VERSION ""

NS_ :

BS_:

BU_: ECU

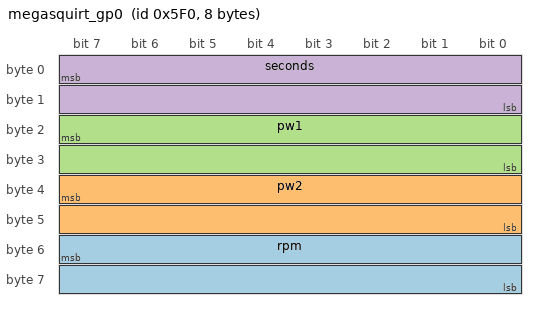
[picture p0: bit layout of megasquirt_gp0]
BO_ 1520 megasquirt_gp0: 8 ECU
 SG_ rpm : 55|16@0+ (1,0) [0|0] "RPM" ECU
 SG_ pw2 : 39|16@0+ (0.001,0) [0|0] "ms" ECU
 SG_ pw1 : 23|16@0+ (0.001,0) [0|0] "ms" ECU
 SG_ seconds : 7|16@0+ (1,0) [0|0] "s" ECU

CM_ SG_ 1520 rpm "Engine RPM";
CM_ SG_ 1520 pw2 "Main pulsewidth bank 2";
CM_ SG_ 1520 pw1 "Main pulsewidth bank 1";
CM_ SG_ 1520 seconds "Seconds ECU has been on";
BA_DEF_  "BusType" STRING ;
BA_DEF_DEF_  "BusType" "CAN";
